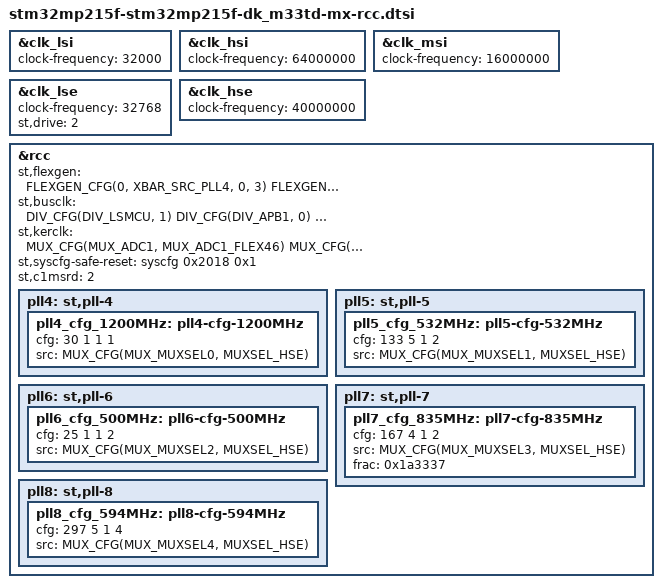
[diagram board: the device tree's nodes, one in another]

&clk_lsi {
	clock-frequency = <32000>;
};

&clk_hsi {
	clock-frequency = <64000000>;
};

&clk_msi {
	clock-frequency = <16000000>;
};

&clk_lse {
	clock-frequency = <32768>;

	/* USER CODE BEGIN clk_lse */
	st,drive = <2>;
	/* USER CODE END clk_lse */
};

&clk_hse {
	clock-frequency = <40000000>;
};

&rcc {
	st,flexgen = <

		FLEXGEN_CFG(0, XBAR_SRC_PLL4, 0, 3)
		FLEXGEN_CFG(1, XBAR_SRC_PLL4, 0, 5)
		FLEXGEN_CFG(2, XBAR_SRC_PLL4, 0, 1)
		FLEXGEN_CFG(3, XBAR_SRC_PLL4, 0, 2)
		FLEXGEN_CFG(4, XBAR_SRC_PLL4, 0, 3)
		FLEXGEN_CFG(5, XBAR_SRC_PLL4, 0, 2)
		FLEXGEN_CFG(8, XBAR_SRC_HSI_KER, 0, 0)
		FLEXGEN_CFG(13, XBAR_SRC_PLL4, 0, 11)
		FLEXGEN_CFG(21, XBAR_SRC_PLL7, 0, 16)
		FLEXGEN_CFG(27, XBAR_SRC_PLL8, 0, 3)
		FLEXGEN_CFG(29, XBAR_SRC_PLL5, 0, 1)
		FLEXGEN_CFG(30, XBAR_SRC_HSE_KER, 0, 1)
		FLEXGEN_CFG(31, XBAR_SRC_PLL5, 0, 19)
		FLEXGEN_CFG(33, XBAR_SRC_HSE_KER, 0, 0)
		FLEXGEN_CFG(38, XBAR_SRC_PLL4, 0, 11)
		FLEXGEN_CFG(40, XBAR_SRC_LSE, 0, 0)
		FLEXGEN_CFG(43, XBAR_SRC_PLL4, 0, 23)
		FLEXGEN_CFG(44, XBAR_SRC_PLL4, 0, 5)
		FLEXGEN_CFG(45, XBAR_SRC_PLL4, 0, 2)
		FLEXGEN_CFG(46, XBAR_SRC_PLL5, 0, 3)
		FLEXGEN_CFG(51, XBAR_SRC_PLL4, 0, 5)
		FLEXGEN_CFG(54, XBAR_SRC_PLL6, 0, 9)
		FLEXGEN_CFG(56, XBAR_SRC_PLL4, 0, 5)
		FLEXGEN_CFG(63, RCC_XBAR_CLKSRC_PLL4, 0, 2)
	>;
	st,busclk = <
		DIV_CFG(DIV_LSMCU, 1)
		DIV_CFG(DIV_APB1, 0)
		DIV_CFG(DIV_APB2, 0)
		DIV_CFG(DIV_APB3, 0)
		DIV_CFG(DIV_APB4, 0)
		DIV_CFG(DIV_APB5, 0)
		DIV_CFG(DIV_APBDBG, 0)
	>;
	st,kerclk = <
		MUX_CFG(MUX_ADC1, MUX_ADC1_FLEX46)
		MUX_CFG(MUX_DTS, MUX_DTS_MSI)

		MUX_CFG(MUX_RTC, MUX_RTC_LSE)

	>;

	/* USER CODE BEGIN rcc */
	st,syscfg-safe-reset = <&syscfg 0x2018 0x1>;
	st,c1msrd = <2>;
	/* USER CODE END rcc */

	pll4:st,pll-4{

		pll4_cfg_1200MHz:pll4-cfg-1200MHz{
			cfg = <30 1 1 1>;
			src = <MUX_CFG(MUX_MUXSEL0, MUXSEL_HSE)>;
		};
	};

	pll5:st,pll-5{

		pll5_cfg_532MHz:pll5-cfg-532MHz{
			cfg = <133 5 1 2>;
			src = <MUX_CFG(MUX_MUXSEL1, MUXSEL_HSE)>;
		};
	};

	pll6:st,pll-6{

		pll6_cfg_500MHz:pll6-cfg-500MHz{
			cfg = <25 1 1 2>;
			src = <MUX_CFG(MUX_MUXSEL2, MUXSEL_HSE)>;
		};
	};

	pll7:st,pll-7{

		/* USER CODE BEGIN pll7 */
		/* USER CODE END pll7 */

		pll7_cfg_835MHz:pll7-cfg-835MHz{
			cfg = <167 4 1 2>;
			src = <MUX_CFG(MUX_MUXSEL3, MUXSEL_HSE)>;
			frac = < 0x1a3337 >;
		};
	};

	pll8:st,pll-8{

		pll8_cfg_594MHz:pll8-cfg-594MHz{
			cfg = <297 5 1 4>;
			src = <MUX_CFG(MUX_MUXSEL4, MUXSEL_HSE)>;
		};
	};
};

/* USER CODE BEGIN addons */
/* USER CODE END addons */
